VERSION "WUFR 23.1.0"

BS_: 1000000 : 0,0

BU_: FLSB DAQ FRSB

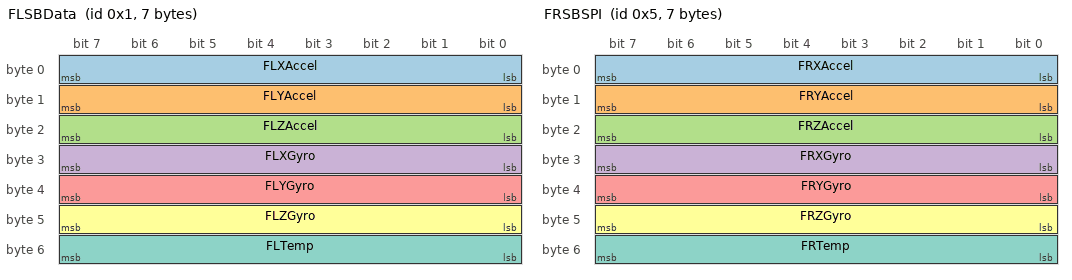
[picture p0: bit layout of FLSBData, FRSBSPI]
BO_ 1 FLSBData: 7 FLSB
 SG_ FLXAccel : 0|8@1- (0.307451,0.153725) [-39.2|39.2] "m/s^2" DAQ
 SG_ FLYAccel : 8|8@1- (0.307451,0.153725) [-39.2|39.2] "m/s^2" DAQ
 SG_ FLZAccel : 16|8@1- (0.307451,0.153725) [-39.2|39.2] "m/s^2" DAQ
 SG_ FLXGyro : 24|8@1+ (1,0) [-80|80] "rad/s" DAQ
 SG_ FLYGyro : 32|8@1+ (1,0) [-80|80] "rad/s" DAQ
 SG_ FLZGyro : 40|8@1+ (1,0) [-80|80] "rad/s" DAQ
 SG_ FLTemp : 48|8@1- (1,0) [-80|80] "rad/s" DAQ

BO_ 5 FRSBSPI: 7 FRSB
 SG_ FRXAccel : 0|8@1- (0.307451,0.153725) [-39.2|39.2] "m/s^2" DAQ
 SG_ FRYAccel : 8|8@1- (0.307451,0.153725) [-39.2|39.2] "m/s^2" DAQ
 SG_ FRZAccel : 16|8@1- (0.307451,0.153725) [-39.2|39.2] "m/s^2" DAQ
 SG_ FRXGyro : 24|8@1+ (1,0) [-80|80] "rad/s" DAQ
 SG_ FRYGyro : 32|8@1+ (1,0) [-80|80] "rad/s" DAQ
 SG_ FRZGyro : 40|8@1+ (1,0) [-80|80] "rad/s" DAQ
 SG_ FRTemp : 48|8@1- (1,0) [-80|80] "rad/s" DAQ

BO_ 6 FRSBAnlg12: 8 FRSB
 SG_ FRAnlg1 : 0|32

CM_ BU_ FLSB "Front left sensor board";
CM_ BU_ FRSB "Front right sensor board";
BA_DEF_DEF_  "GenMsgCycleTime" 100;
